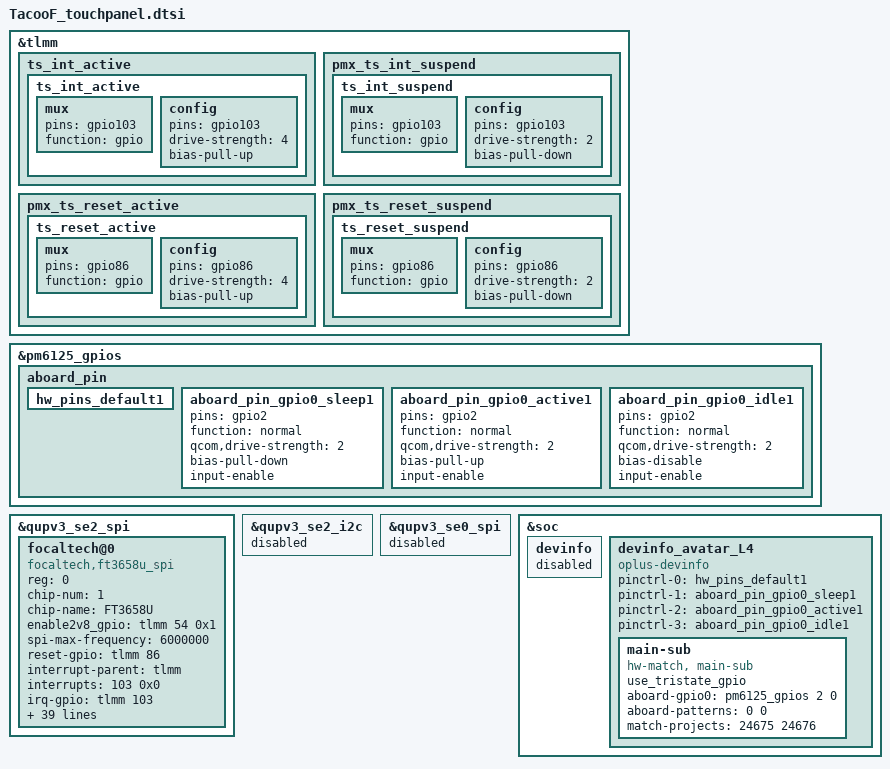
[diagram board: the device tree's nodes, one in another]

&tlmm {
	ts_int_active {
 		ts_int_active: ts_int_active {
 			mux {
 				pins = "gpio103";
 				function = "gpio";
 			};

 			config {
 				pins = "gpio103";
 				drive-strength = <4>;
 				bias-pull-up;
 			};
 		};
 	};

 	pmx_ts_int_suspend {
 		ts_int_suspend: ts_int_suspend {
 			mux {
 				pins = "gpio103";
 				function = "gpio";
 			};

 			config {
 				pins = "gpio103";
 				drive-strength = <2>;
 				bias-pull-down;
 			};
 		};
 	};

 	pmx_ts_reset_active {
 		ts_reset_active: ts_reset_active {
 			mux {
 				pins = "gpio86";
 				function = "gpio";
 			};

 			config {
 				pins = "gpio86";
 				drive-strength = <4>;
 				bias-pull-up;
 			};
 		};
 	};

 	pmx_ts_reset_suspend {
 		ts_reset_suspend: ts_reset_suspend {
 			mux {
 				pins = "gpio86";
 				function = "gpio";
 			};

 			config {
 				pins = "gpio86";
 				drive-strength = <2>;
 				bias-pull-down;
 			};
 		};
 	};

};

&pm6125_gpios {
         aboard_pin {
                 hw_pins_default1:hw_pins_default1 {
				};

		aboard_pin_gpio0_sleep1:aboard_pin_gpio0_sleep1 {
			pins = "gpio2";
			function = "normal";
			qcom,drive-strength = <2>;
			bias-pull-down;
			input-enable;
		};
		aboard_pin_gpio0_active1:aboard_pin_gpio0_active1 {
			pins = "gpio2";
			function = "normal";
			qcom,drive-strength = <2>;
			bias-pull-up;
			input-enable;
		};

		aboard_pin_gpio0_idle1:aboard_pin_gpio0_idle1 {
			pins = "gpio2";
			function = "normal";
			qcom,drive-strength = <2>;
			bias-disable;
			input-enable;
		};
		};
};


&qupv3_se2_spi {
        status = "ok";
        focaltech@0 {
                 compatible = "focaltech,ft3658u_spi";
                 reg = <0>;
                 chip-num = <1>;
                 chip-name = "FT3658U";
                 status = "ok";
                /* Power Config */
                 enable2v8_gpio = <&tlmm 54 0x1>;
                 spi-max-frequency = <6000000>;    //4800000,9600000,15000000,19200000
                 reset-gpio = <&tlmm 86 0x00>;
                 interrupt-parent = <&tlmm>;
                 interrupts = <103 0x0>;
                 irq-gpio = <&tlmm 103 0x2002>;
                 cs-gpio = <&tlmm 80 0x00>;

                 panel_type = <8 8>;
                 project_id = <24675>;
                 touchpanel,max-num-support = <10>;
                 touchpanel,tx-rx-num = <16 34>;
                 touchpanel,panel-coords = <8640 19200>;
                 touchpanel,display-coords = <1080 2400>;
                 touchpanel,touchmajor-limit = <0 54>;
                 touchpanel,smooth-level = <255 15 40 80 160 240>;
                 touchpanel,sensitive-level = <255 30 25 20 10 8>;
                 touchpanel,high-frame-rate-time = <20>;
                 touchpanel,single-optimized-time = <8>;
				 
                 tp_type = <8 8>;
                 platform_support_project = <24675 24676>;
                 platform_support_project_dir = <24675 24675>;
                 firmware_name = "ft3658U_00";
                 platform_support_project_commandline = "default_commandline", "default_commandline";


                 /* SW Support Feature Control */
                 sportify_aod_gesture_support;
                 irq_need_dev_resume_ok;
                 black_gesture_support;
                 fw_edge_limit_support;
                 pressure_report_support;
                 charger_pump_support;
                 game_switch_support;
                 smart_gesture_support;
                 fw_update_app_support;
                 health_monitor_support;
                 fingerprint_underscreen_support;
                 black_gesture_indep_support;
                 exception_upload_support;
                 //esd_handle_support;
                 new_set_irq_wake_support;
                 // focalt x8 resolution config
                 high_resolution_support;
                 high_resolution_support_x8;
                 switch_game_rate_support;
                 disable_suspend_irq_handler_support;
                 report_rate_game_value = <1>;

                 /*
                 *Virtual Key Config:
                 *1:touchpanel,button-type: <virtualkey_type  supportted_button-map>
                 *virtualkey_type:
                 *Type 1: using board_properties
                 *Type 2: using same IC (button zone&& touch zone are seprate)
                 *Type 3: using diffrent IC (button zone&& touch zone are seprate)
                 *Type 4: No need of virtual key process
                 *supportted_button-map:select|menu|home|back
                 *
                 *2:touchpanel,button-map
                 *type (X1,Y1)(X2,Y2)(X3,Y3)(Width_X,Hight_Y)--Only when button-type is 0
                 */
                 touchpanel,button-type = <4>;
                 touchpanel.button-TRx = <0 0>;
         };
 };

&qupv3_se2_i2c {

	status = "disabled";

 };

&qupv3_se0_spi {

	status = "disabled";

 };

&soc {

	devinfo {
                 status = "disabled";
         };

         devinfo_avatar_L4 {
                 compatible = "oplus-devinfo";

                 pinctrl-names = "default", "sleep", "active", "idle";
                 pinctrl-0 = <&hw_pins_default1>;
                 pinctrl-1 = <&aboard_pin_gpio0_sleep1>;
                 pinctrl-2 = <&aboard_pin_gpio0_active1>;
                 pinctrl-3 = <&aboard_pin_gpio0_idle1>;
                 main-sub {
                         use_tristate_gpio;
                         compatible = "hw-match, main-sub";
                         aboard-gpio0 = <&pm6125_gpios 2 0>;
                         aboard-patterns = <0 0>;    /*0[high-resistance] 1[pull-down] 2[pull-up]*/
                         /*main board*/
                         match-projects = <24675 24676>;
                 };
         };

};

